# ESP32-S2 register map
Vendor: ESPRESSIF SYSTEMS (SHANGHAI) CO., LTD.; Series: ESP32 S-Series; File version: 20
CPU: Xtensa LX7 r0p0, little endian, no MPU, no FPU, 0 interrupt priority bits
Address unit: 32 bits
Registers are 32-bit, read-write, reset 0x0 unless marked. A register's access mark holds for its fields unless they carry their own. Offsets are from the block's base; [hi:lo] are bit positions; {n}, {i} and the like mark numbered series.

## EFUSE — eFuse Controller
Base 0x3F41A000
{0x0+4i} PGM_DATA{i} (i=0..7) — Register {i} that stores data to be programmed.
  [31:0] PGM_DATA — The content of the %sth 32-bit data to be programmed.
{0x20+4i} PGM_CHECK_VALUE{i} (i=0..2) — Register {i} that stores the RS code to be programmed.
  [31:0] PGM_RS_DATA — The content of the %sth 32-bit RS code to be programmed.
0x2C RD_WR_DIS ro — Register 0 of BLOCK0.
  [31:0] WR_DIS — Disables programming of individual eFuses.
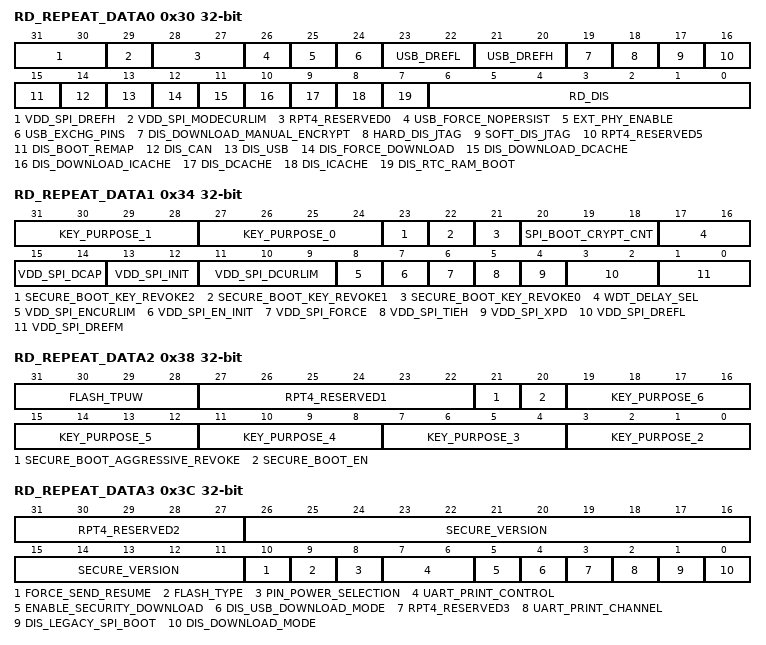
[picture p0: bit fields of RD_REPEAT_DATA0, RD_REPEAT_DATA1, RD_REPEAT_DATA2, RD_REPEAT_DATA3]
0x30 RD_REPEAT_DATA0 ro — Register 1 of BLOCK0.
  [31:30] VDD_SPI_DREFH — SPI regulator high voltage reference.
  [29] VDD_SPI_MODECURLIM — SPI regulator switches current limit mode.
  [28:27] RPT4_RESERVED0 — Reserved (used for four backups method).
  [26] USB_FORCE_NOPERSIST — If set, forces USB BVALID to 1.
  [25] EXT_PHY_ENABLE — Set this bit to enable external USB PHY.
  [24] USB_EXCHG_PINS — Set this bit to exchange USB D+ and D- pins.
  [23:22] USB_DREFL — Controls single-end input threshold vrefl, 0.8 V to 1.04 V with step of 80 mV, stored in eFuse.
  [21:20] USB_DREFH — Controls single-end input threshold vrefh, 1.76 V to 2 V with step of 80 mV, stored in eFuse.
  [19] DIS_DOWNLOAD_MANUAL_ENCRYPT — Disables flash encryption when in download boot modes.
  [18] HARD_DIS_JTAG — Hardware disables JTAG permanently.
  [17] SOFT_DIS_JTAG — Software disables JTAG. When software disabled, JTAG can be activated temporarily by HMAC peripheral.
  [16] RPT4_RESERVED5 — Reserved (used for four backups method).
  [15] DIS_BOOT_REMAP — Disables capability to Remap RAM to ROM address space.
  [14] DIS_CAN — Set this bit to disable the TWAI Controller function.
  [13] DIS_USB — Set this bit to disable USB OTG function.
  [12] DIS_FORCE_DOWNLOAD — Set this bit to disable the function that forces chip into download mode.
  [11] DIS_DOWNLOAD_DCACHE — Disables Dcache when SoC is in Download mode.
  [10] DIS_DOWNLOAD_ICACHE — Disables Icache when SoC is in Download mode.
  [9] DIS_DCACHE — Set this bit to disable Dcache.
  [8] DIS_ICACHE — Set this bit to disable Icache.
  [7] DIS_RTC_RAM_BOOT — Reserved.
  [6:0] RD_DIS — Disables software reading from individual eFuse blocks (BLOCK4-10).
0x34 RD_REPEAT_DATA1 ro — Register 2 of BLOCK0.
  [31:28] KEY_PURPOSE_1 — Purpose of KEY1. Refer to Table Key Purpose Values.
  [27:24] KEY_PURPOSE_0 — Purpose of KEY0. Refer to Table Key Purpose Values.
  [23] SECURE_BOOT_KEY_REVOKE2 — If set, revokes use of secure boot key digest 2.
  [22] SECURE_BOOT_KEY_REVOKE1 — If set, revokes use of secure boot key digest 1.
  [21] SECURE_BOOT_KEY_REVOKE0 — If set, revokes use of secure boot key digest 0.
  [20:18] SPI_BOOT_CRYPT_CNT — Enables encryption and decryption, when an SPI boot mode is set. Feature is enabled 1 or 3 bits are set in the eFuse, disabled otherwise.
  [17:16] WDT_DELAY_SEL — Selects RTC watchdog timeout threshold at startup. 0: 40,000 slow clock cycles. 1: 80,000 slow clock cycles. 2: 160,000 slow clock cycles. 3: 320,000 slow clock cycles.
  [15:14] VDD_SPI_DCAP — Prevents SPI regulator from overshoot.
  [13:12] VDD_SPI_INIT — Adds resistor from LDO output to ground. 0: no resistance. 1: 6 K. 2: 4 K. 3: 2 K.
  [11:9] VDD_SPI_DCURLIM — Tunes the current limit threshold of SPI regulator when tieh=0, about 800 mA/(8+d).
  [8] VDD_SPI_ENCURLIM — Set SPI regulator to 1 to enable output current limit.
  [7] VDD_SPI_EN_INIT — Set SPI regulator to 0 to configure init[1:0]=0.
  [6] VDD_SPI_FORCE — Set this bit to use XPD_VDD_PSI_REG and VDD_SPI_TIEH to configure VDD_SPI LDO.
  [5] VDD_SPI_TIEH — If VDD_SPI_FORCE is 1, determines VDD_SPI voltage. 0: VDD_SPI connects to 1.8 V LDO. 1: VDD_SPI connects to VDD_RTC_IO.
  [4] VDD_SPI_XPD — If VDD_SPI_FORCE is 1, this value determines if the VDD_SPI regulator is powered on.
  [3:2] VDD_SPI_DREFL — SPI regulator low voltage reference.
  [1:0] VDD_SPI_DREFM — SPI regulator medium voltage reference.
0x38 RD_REPEAT_DATA2 ro — Register 3 of BLOCK0.
  [31:28] FLASH_TPUW — Configures flash startup delay after SoC power-up, in unit of (ms/2). When the value is 15, delay is 7.5 ms.
  [27:22] RPT4_RESERVED1 — Reserved (used for four backups method).
  [21] SECURE_BOOT_AGGRESSIVE_REVOKE — Set this bit to enable aggressive secure boot key revocation mode.
  [20] SECURE_BOOT_EN — Set this bit to enable secure boot.
  [4n-5:4n-8] KEY_PURPOSE_{n} (n=2..6) — Purpose of KEY{n}. Refer to Table Key Purpose Values.
0x3C RD_REPEAT_DATA3 ro — Register 4 of BLOCK0.
  [31:27] RPT4_RESERVED2 — Reserved (used for four backups method).
  [26:11] SECURE_VERSION — Secure version (used by ESP-IDF anti-rollback feature).
  [10] FORCE_SEND_RESUME — If set, forces ROM code to send an SPI flash resume command during SPI boot.
  [9] FLASH_TYPE — SPI flash type. 0: maximum four data lines, 1: eight data lines.
  [8] PIN_POWER_SELECTION — Set default power supply for GPIO33-GPIO37, set when SPI flash is initialized. 0: VDD3P3_CPU. 1: VDD_SPI.
  [7:6] UART_PRINT_CONTROL — Set the default UART boot message output mode. 00: Enabled. 01: Enable when GPIO46 is low at reset. 10: Enable when GPIO46 is high at reset. 11: Disabled.
  [5] ENABLE_SECURITY_DOWNLOAD — Set this bit to enable secure UART download mode (read/write flash only).
  [4] DIS_USB_DOWNLOAD_MODE — Set this bit to disable use of USB OTG in UART download boot mode.
  [3] RPT4_RESERVED3 — Reserved (used for four backups method).
  [2] UART_PRINT_CHANNEL — Selects the default UART for printing boot messages. 0: UART0. 1: UART1.
  [1] DIS_LEGACY_SPI_BOOT — Set this bit to disable Legacy SPI boot mode.
  [0] DIS_DOWNLOAD_MODE — Set this bit to disable all download boot modes.
0x40 RD_REPEAT_DATA4 ro — Register 5 of BLOCK0.
  [23:0] RPT4_RESERVED4 — Reserved (used for four backups method).
0x44 RD_MAC_SPI_SYS_0 ro — Register 0 of BLOCK1.
  [31:0] MAC_0 — Stores the low 32 bits of MAC address.
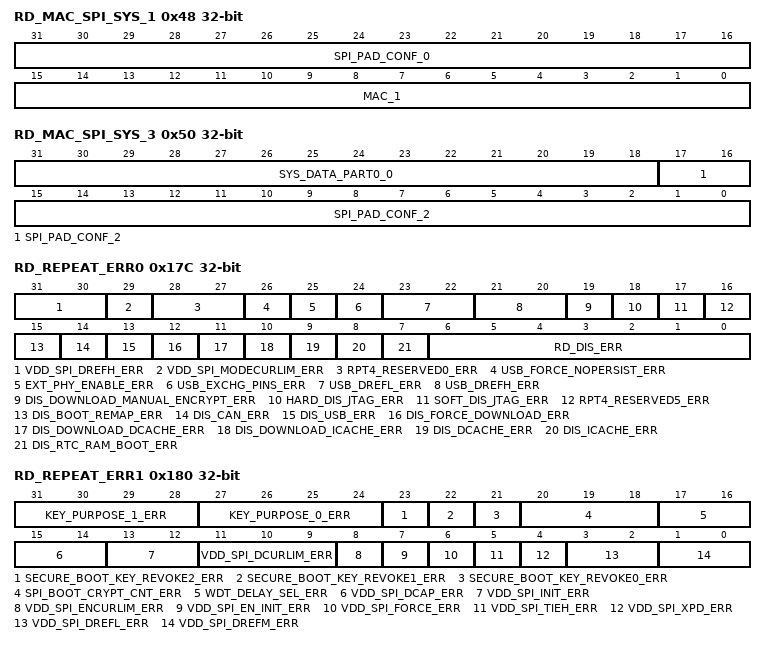
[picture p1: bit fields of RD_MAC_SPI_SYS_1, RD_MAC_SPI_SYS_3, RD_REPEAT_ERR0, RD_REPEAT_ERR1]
0x48 RD_MAC_SPI_SYS_1 ro — Register 1 of BLOCK1.
  [31:16] SPI_PAD_CONF_0 — Stores the zeroth part of SPI_PAD_CONF.
  [15:0] MAC_1 — Stores the high 16 bits of MAC address.
0x4C RD_MAC_SPI_SYS_2 ro — Register 2 of BLOCK1.
  [31:0] SPI_PAD_CONF_1 — Stores the first part of SPI_PAD_CONF.
0x50 RD_MAC_SPI_SYS_3 ro — Register 3 of BLOCK1.
  [31:18] SYS_DATA_PART0_0 — Stores the zeroth part of the zeroth part of system data.
  [17:0] SPI_PAD_CONF_2 — Stores the second part of SPI_PAD_CONF.
0x54 RD_MAC_SPI_SYS_4 ro — Register 4 of BLOCK1.
  [31:0] SYS_DATA_PART0_1 — Stores the fist part of the zeroth part of system data.
0x58 RD_MAC_SPI_SYS_5 ro — Register 5 of BLOCK1.
  [31:0] SYS_DATA_PART0_2 — Stores the second part of the zeroth part of system data.
{0x5C+4i} RD_SYS_DATA_PART1_{i} (i=0..7) ro — Register {i} of BLOCK2 (system).
  [31:0] SYS_DATA_PART1 — Stores the %sth 32 bits of the first part of system data.
{0x7C+4i} RD_USR_DATA{i} (i=0..7) ro — Register {i} of BLOCK3 (user).
  [31:0] USR_DATA — Stores the %sth 32 bits of BLOCK3 (user).
{0x9C+4i} RD_KEY0_DATA{i} (i=0..7) ro — Register {i} of BLOCK4 (KEY0).
  [31:0] KEY0_DATA — Stores the %sth 32 bits of KEY0.
{0xBC+4i} RD_KEY1_DATA{i} (i=0..7) ro — Register {i} of BLOCK5 (KEY1).
  [31:0] KEY1_DATA — Stores the %sth 32 bits of KEY1.
{0xDC+4i} RD_KEY2_DATA{i} (i=0..7) ro — Register {i} of BLOCK6 (KEY2).
  [31:0] KEY2_DATA — Stores the %sth 32 bits of KEY2.
{0xFC+4i} RD_KEY3_DATA{i} (i=0..7) ro — Register {i} of BLOCK7 (KEY3).
  [31:0] KEY3_DATA — Stores the %sth 32 bits of KEY3.
{0x11C+4i} RD_KEY4_DATA{i} (i=0..7) ro — Register {i} of BLOCK8 (KEY4).
  [31:0] KEY4_DATA — Stores the %sth 32 bits of KEY4.
{0x13C+4i} RD_KEY5_DATA{i} (i=0..7) ro — Register {i} of BLOCK9 (KEY5).
  [31:0] KEY5_DATA — Stores the %sth 32 bits of KEY5.
{0x15C+4i} RD_SYS_DATA_PART2_{i} (i=0..7) ro — Register {i} of BLOCK10 (system).
  [31:0] SYS_DATA_PART2 — Stores the %sth 32 bits of the 2nd part of system data.
0x17C RD_REPEAT_ERR0 ro — Programming error record register 0 of BLOCK0.
  [31:30] VDD_SPI_DREFH_ERR — Any bit equal to 1 denotes a programming error in EFUSE_VDD_SPI_DREFH.
  [29] VDD_SPI_MODECURLIM_ERR — Any bit equal to 1 denotes a programming error in EFUSE_VDD_SPI_MODECURLIM.
  [28:27] RPT4_RESERVED0_ERR — Any bit equal to 1 denotes a programming error in EFUSE_RPT4_RESERVED0.
  [26] USB_FORCE_NOPERSIST_ERR — Any bit equal to 1 denotes a programming error in EFUSE_USB_FORCE_NOPERSIST.
  [25] EXT_PHY_ENABLE_ERR — Any bit equal to 1 denotes a programming error in EFUSE_EXT_PHY_ENABLE.
  [24] USB_EXCHG_PINS_ERR — Any bit equal to 1 denotes a programming error in EFUSE_USB_EXCHG_PINS.
  [23:22] USB_DREFL_ERR — Any bit equal to 1 denotes a programming error in EFUSE_USB_DREFL.
  [21:20] USB_DREFH_ERR — Any bit equal to 1 denotes a programming error in EFUSE_USB_DREFH.
  [19] DIS_DOWNLOAD_MANUAL_ENCRYPT_ERR — Any bit equal to 1 denotes a programming error in EFUSE_DIS_DOWNLOAD_MANUAL_ENCRYPT.
  [18] HARD_DIS_JTAG_ERR — Any bit equal to 1 denotes a programming error in EFUSE_HARD_DIS_JTAG.
  [17] SOFT_DIS_JTAG_ERR — Any bit equal to 1 denotes a programming error in EFUSE_SOFT_DIS_JTAG.
  [16] RPT4_RESERVED5_ERR — Any bit equal to 1 denotes a programming error in EFUSE_RPT4_RESERVED5.
  [15] DIS_BOOT_REMAP_ERR — Any bit equal to 1 denotes a programming error in EFUSE_DIS_BOOT_REMAP.
  [14] DIS_CAN_ERR — Any bit equal to 1 denotes a programming error in EFUSE_DIS_CAN.
  [13] DIS_USB_ERR — Any bit equal to 1 denotes a programming error in EFUSE_DIS_USB.
  [12] DIS_FORCE_DOWNLOAD_ERR — Any bit equal to 1 denotes a programming error in EFUSE_DIS_FORCE_DOWNLOAD.
  [11] DIS_DOWNLOAD_DCACHE_ERR — Any bit equal to 1 denotes a programming error in EFUSE_DIS_DOWNLOAD_DCACHE.
  [10] DIS_DOWNLOAD_ICACHE_ERR — Any bit equal to 1 denotes a programming error in EFUSE_DIS_DOWNLOAD_ICACHE.
  [9] DIS_DCACHE_ERR — Any bit equal to 1 denotes a programming error in EFUSE_DIS_DCACHE.
  [8] DIS_ICACHE_ERR — Any bit equal to 1 denotes a programming error in EFUSE_DIS_ICACHE.
  [7] DIS_RTC_RAM_BOOT_ERR — Any bit equal to 1 denotes a programming error in EFUSE_DIS_RTC_RAM_BOOT.
  [6:0] RD_DIS_ERR — Any bit equal to 1 denotes a programming error in EFUSE_RD_DIS.
0x180 RD_REPEAT_ERR1 ro — Programming error record register 1 of BLOCK0.
  [31:28] KEY_PURPOSE_1_ERR — Any bit equal to 1 denotes a programming error in EFUSE_KEY_PURPOSE_1.
  [27:24] KEY_PURPOSE_0_ERR — Any bit equal to 1 denotes a programming error in EFUSE_KEY_PURPOSE_0.
  [23] SECURE_BOOT_KEY_REVOKE2_ERR — Any bit equal to 1 denotes a programming error in EFUSE_SECURE_BOOT_KEY_REVOKE2.
  [22] SECURE_BOOT_KEY_REVOKE1_ERR — Any bit equal to 1 denotes a programming error in EFUSE_SECURE_BOOT_KEY_REVOKE1.
  [21] SECURE_BOOT_KEY_REVOKE0_ERR — Any bit equal to 1 denotes a programming error in EFUSE_SECURE_BOOT_KEY_REVOKE0.
  [20:18] SPI_BOOT_CRYPT_CNT_ERR — Any bit equal to 1 denotes a programming error in EFUSE_SPI_BOOT_CRYPT_CNT.
  [17:16] WDT_DELAY_SEL_ERR — Any bit equal to 1 denotes a programming error in EFUSE_WDT_DELAY_SEL.
  [15:14] VDD_SPI_DCAP_ERR — Any bit equal to 1 denotes a programming error in EFUSE_VDD_SPI_DCAP.
  [13:12] VDD_SPI_INIT_ERR — Any bit equal to 1 denotes a programming error in EFUSE_VDD_SPI_INIT.
  [11:9] VDD_SPI_DCURLIM_ERR — Any bit equal to 1 denotes a programming error in EFUSE_VDD_SPI_DCURLIM.
  [8] VDD_SPI_ENCURLIM_ERR — Any bit equal to 1 denotes a programming error in EFUSE_VDD_SPI_ENCURLIM.
  [7] VDD_SPI_EN_INIT_ERR — Any bit equal to 1 denotes a programming error in EFUSE_VDD_SPI_EN_INIT.
  [6] VDD_SPI_FORCE_ERR — Any bit equal to 1 denotes a programming error in EFUSE_VDD_SPI_FORCE.
  [5] VDD_SPI_TIEH_ERR — Any bit equal to 1 denotes a programming error in EFUSE_VDD_SPI_TIEH.
  [4] VDD_SPI_XPD_ERR — Any bit equal to 1 denotes a programming error in EFUSE_VDD_SPI_XPD.
  [3:2] VDD_SPI_DREFL_ERR — Any bit equal to 1 denotes a programming error in EFUSE_VDD_SPI_DREFL.
  [1:0] VDD_SPI_DREFM_ERR — Any bit equal to 1 denotes a programming error in EFUSE_VDD_SPI_DREFM.
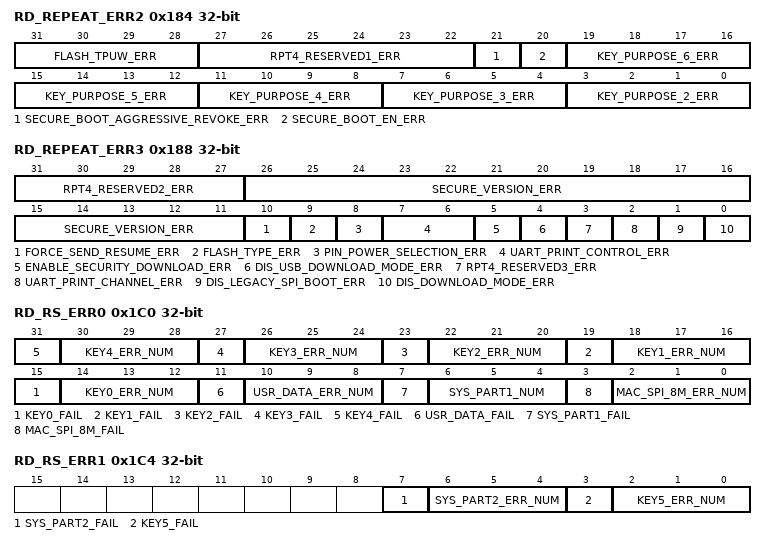
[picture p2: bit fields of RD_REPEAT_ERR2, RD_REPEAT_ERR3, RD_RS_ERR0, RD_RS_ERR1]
0x184 RD_REPEAT_ERR2 ro — Programming error record register 2 of BLOCK0.
  [31:28] FLASH_TPUW_ERR — Any bit equal to 1 denotes a programming error in EFUSE_FLASH_TPUW.
  [27:22] RPT4_RESERVED1_ERR — Any bit equal to 1 denotes a programming error in EFUSE_RPT4_RESERVED1.
  [21] SECURE_BOOT_AGGRESSIVE_REVOKE_ERR — Any bit equal to 1 denotes a programming error in EFUSE_SECURE_BOOT_AGGRESSIVE_REVOKE.
  [20] SECURE_BOOT_EN_ERR — Any bit equal to 1 denotes a programming error in EFUSE_SECURE_BOOT_EN.
  [4n-5:4n-8] KEY_PURPOSE_{n}_ERR (n=2..6) — Any bit equal to 1 denotes a programming error in EFUSE_KEY_PURPOSE_{n}.
0x188 RD_REPEAT_ERR3 ro — Programming error record register 3 of BLOCK0.
  [31:27] RPT4_RESERVED2_ERR — Any bit equal to 1 denotes a programming error in EFUSE_RPT4_RESERVED2.
  [26:11] SECURE_VERSION_ERR — Any bit equal to 1 denotes a programming error in EFUSE_SECURE_VERSION.
  [10] FORCE_SEND_RESUME_ERR — Any bit equal to 1 denotes a programming error in EFUSE_FORCE_SEND_RESUME.
  [9] FLASH_TYPE_ERR — Any bit equal to 1 denotes a programming error in EFUSE_FLASH_TYPE.
  [8] PIN_POWER_SELECTION_ERR — Any bit equal to 1 denotes a programming error in EFUSE_PIN_POWER_SELECTION.
  [7:6] UART_PRINT_CONTROL_ERR — Any bit equal to 1 denotes a programming error in EFUSE_UART_PRINT_CONTROL.
  [5] ENABLE_SECURITY_DOWNLOAD_ERR — Any bit equal to 1 denotes a programming error in EFUSE_ENABLE_SECURITY_DOWNLOAD.
  [4] DIS_USB_DOWNLOAD_MODE_ERR — Any bit equal to 1 denotes a programming error in EFUSE_DIS_USB_DOWNLOAD_MODE.
  [3] RPT4_RESERVED3_ERR — Any bit equal to 1 denotes a programming error in EFUSE_RPT4_RESERVED3.
  [2] UART_PRINT_CHANNEL_ERR — Any bit equal to 1 denotes a programming error in EFUSE_UART_PRINT_CHANNEL.
  [1] DIS_LEGACY_SPI_BOOT_ERR — Any bit equal to 1 denotes a programming error in EFUSE_DIS_LEGACY_SPI_BOOT.
  [0] DIS_DOWNLOAD_MODE_ERR — Any bit equal to 1 denotes a programming error in EFUSE_DIS_DOWNLOAD_MODE.
0x190 RD_REPEAT_ERR4 ro — Programming error record register 4 of BLOCK0.
  [23:0] RPT4_RESERVED4_ERR — If any bit in RPT4_RESERVED4 is 1, there is a programming error in EFUSE_RPT4_RESERVED4.
0x1C0 RD_RS_ERR0 ro — Programming error record register 0 of BLOCK1-10.
  [4n+15] KEY{n}_FAIL (n=0..4) — 0: Means no failure and that the data of KEY{n} is reliable. 1: Means that programming KEY{n} failed and the number of error bytes is over 5.
  [4n+14:4n+12] KEY{n}_ERR_NUM (n=0..4) — The value of this signal means the number of error bytes in KEY{n}.
  [11] USR_DATA_FAIL — 0: Means no failure and that the data of BLOCK3 is reliable. 1: Means that programming BLOCK3 data failed and the number of error bytes is over 5.
  [10:8] USR_DATA_ERR_NUM — The value of this signal means the number of error bytes in BLOCK3.
  [7] SYS_PART1_FAIL — 0: Means no failure and that the data of BLOCK2 is reliable. 1: Means that programming BLOCK2 data failed and the number of error bytes is over 5.
  [6:4] SYS_PART1_NUM — The value of this signal means the number of error bytes in BLOCK2.
  [3] MAC_SPI_8M_FAIL — 0: Means no failure and that the data of BLOCK1 is reliable. 1: Means that programming BLOCK1 data failed and the number of error bytes is over 5.
  [2:0] MAC_SPI_8M_ERR_NUM — The value of this signal means the number of error bytes in BLOCK1.
0x1C4 RD_RS_ERR1 ro — Programming error record register 1 of BLOCK1-10.
  [7] SYS_PART2_FAIL — 0: Means no failure and that the data of BLOCK10 is reliable. 1: Means that programming BLOCK10 data failed and the number of error bytes is over 5.
  [6:4] SYS_PART2_ERR_NUM — The value of this signal means the number of error bytes in BLOCK10.
  [3] KEY5_FAIL — 0: Means no failure and that the data of KEY5 is reliable. 1: Means that programming user data failed and the number of error bytes is over 5.
  [2:0] KEY5_ERR_NUM — The value of this signal means the number of error bytes in KEY5.
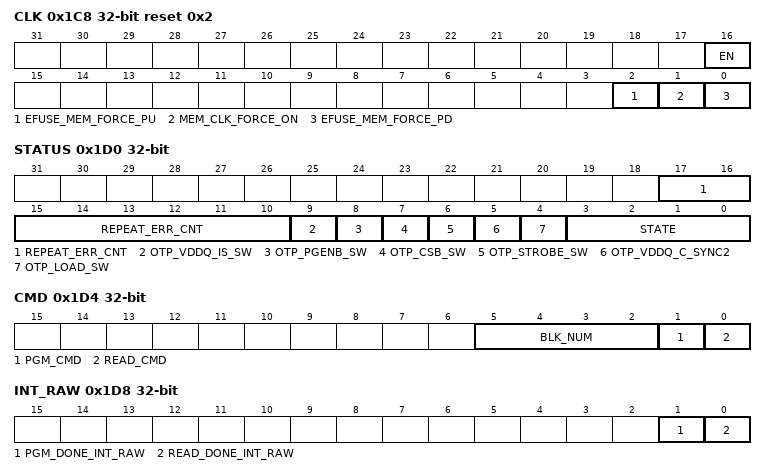
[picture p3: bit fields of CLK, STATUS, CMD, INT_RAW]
0x1C8 CLK reset 0x2 — eFuse clock configuration register.
  [16] EN — If set, forces to enable clock signal of eFuse memory.
  [2] EFUSE_MEM_FORCE_PU — If set, forces eFuse SRAM into working mode.
  [1] MEM_CLK_FORCE_ON — If set, forces to activate clock signal of eFuse SRAM.
  [0] EFUSE_MEM_FORCE_PD — If set, forces eFuse SRAM into power-saving mode.
0x1CC CONF — eFuse operation mode configuration register.
  [15:0] OP_CODE — 0x5A5A: Operate programming command. 0x5AA5: Operate read command.
0x1D0 STATUS ro — eFuse status register.
  [17:10] REPEAT_ERR_CNT — Indicates the number of error bits during programming BLOCK0.
  [9] OTP_VDDQ_IS_SW — The value of OTP_VDDQ_IS_SW.
  [8] OTP_PGENB_SW — The value of OTP_PGENB_SW.
  [7] OTP_CSB_SW — The value of OTP_CSB_SW.
  [6] OTP_STROBE_SW — The value of OTP_STROBE_SW.
  [5] OTP_VDDQ_C_SYNC2 — The value of OTP_VDDQ_C_SYNC2.
  [4] OTP_LOAD_SW — The value of OTP_LOAD_SW.
  [3:0] STATE — Indicates the state of the eFuse state machine.
0x1D4 CMD — eFuse command register.
  [5:2] BLK_NUM — The serial number of the block to be programmed. Value 0-10 corresponds to block number 0-10, respectively.
  [1] PGM_CMD — Set this bit to send programming command.
  [0] READ_CMD — Set this bit to send read command.
0x1D8 INT_RAW ro — eFuse raw interrupt register.
  [1] PGM_DONE_INT_RAW — The raw bit signal for pgm_done interrupt.
  [0] READ_DONE_INT_RAW — The raw bit signal for read_done interrupt.
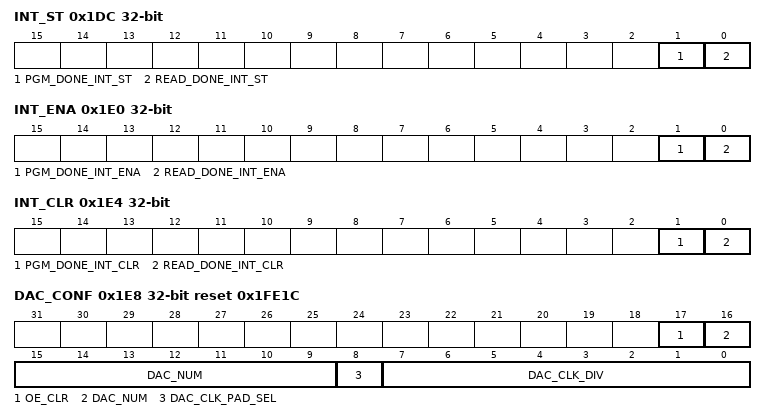
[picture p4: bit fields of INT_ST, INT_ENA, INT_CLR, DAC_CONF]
0x1DC INT_ST ro — eFuse interrupt status register.
  [1] PGM_DONE_INT_ST — The status signal for pgm_done interrupt.
  [0] READ_DONE_INT_ST — The status signal for read_done interrupt.
0x1E0 INT_ENA — eFuse interrupt enable register.
  [1] PGM_DONE_INT_ENA — The enable signal for pgm_done interrupt.
  [0] READ_DONE_INT_ENA — The enable signal for read_done interrupt.
0x1E4 INT_CLR wo — eFuse interrupt clear register.
  [1] PGM_DONE_INT_CLR — The clear signal for pgm_done interrupt.
  [0] READ_DONE_INT_CLR — The clear signal for read_done interrupt.
0x1E8 DAC_CONF reset 0x1FE1C — Controls the eFuse programming voltage.
  [17] OE_CLR — Reduces the power supply of the programming voltage.
  [16:9] DAC_NUM — Controls the rising period of the programming voltage.
  [8] DAC_CLK_PAD_SEL — Don't care.
  [7:0] DAC_CLK_DIV — Controls the division factor of the rising clock of the programming voltage.
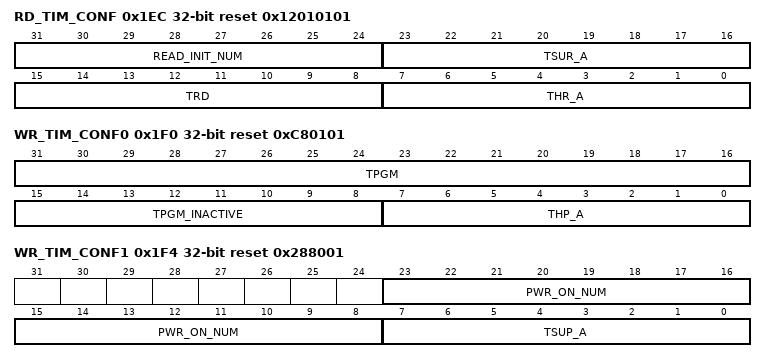
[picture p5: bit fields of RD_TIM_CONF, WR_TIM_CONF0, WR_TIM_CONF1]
0x1EC RD_TIM_CONF reset 0x12010101 — Configures read timing parameters.
  [31:24] READ_INIT_NUM — Configures the initial read time of eFuse.
  [23:16] TSUR_A — Configures the setup time of read operation.
  [15:8] TRD — Configures the length of pulse of read operation.
  [7:0] THR_A — Configures the hold time of read operation.
0x1F0 WR_TIM_CONF0 reset 0xC80101 — Configuration register 0 of eFuse programming timing parameters.
  [31:16] TPGM — Configures the length of pulse during programming 1 to eFuse.
  [15:8] TPGM_INACTIVE — Configures the length of pulse during programming 0 to eFuse.
  [7:0] THP_A — Configures the hold time of programming operation.
0x1F4 WR_TIM_CONF1 reset 0x288001 — Configuration register 1 of eFuse programming timing parameters.
  [23:8] PWR_ON_NUM — Configures the power up time for VDDQ.
  [7:0] TSUP_A — Configures the setup time of programming operation.
0x1F8 WR_TIM_CONF2 reset 0x190 — Configuration register 2 of eFuse programming timing parameters.
  [15:0] PWR_OFF_NUM — Configures the power outage time for VDDQ.
0x1FC DATE reset 0x19081100 — Version control register.
